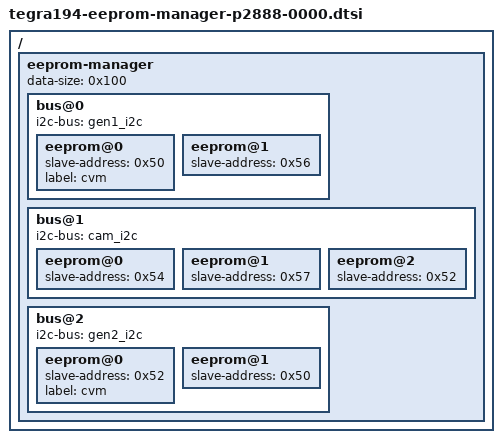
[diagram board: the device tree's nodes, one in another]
/*
 * Copyright (c) 2017-2020, NVIDIA CORPORATION.  All rights reserved.
 *
 * This program is free software; you can redistribute it and/or modify it
 * under the terms and conditions of the GNU General Public License,
 * version 2, as published by the Free Software Foundation.
 *
 * This program is distributed in the hope it will be useful, but WITHOUT
 * ANY WARRANTY; without even the implied warranty of MERCHANTABILITY or
 * FITNESS FOR A PARTICULAR PURPOSE.  See the GNU General Public License for
 * more details.
 *
 * You should have received a copy of the GNU General Public License
 * along with this program.  If not, see <http://www.gnu.org/licenses/>.
 */

/ {
	eeprom-manager {
		data-size = <0x100>;
		bus@0 {
			i2c-bus = <&gen1_i2c>;
			eeprom@0 {
				slave-address = <0x50>;
				label = "cvm";
			};
			eeprom@1 {
				slave-address = <0x56>;
			};
		};
		bus@1 {
			i2c-bus = <&cam_i2c>;
			eeprom@0 {
				slave-address = <0x54>;
			};
			eeprom@1 {
				slave-address = <0x57>;
			};
			eeprom@2 {
				slave-address = <0x52>;
			};
		};
		bus@2 {
			i2c-bus = <&gen2_i2c>;
			eeprom@0 {
				slave-address = <0x52>;
				label = "cvm";
			};
			eeprom@1 {
				slave-address = <0x50>;
			};
		};
	};
};
